# T113-S3 register map
Vendor: Allwinner; Series: T113-S3; File version: 0.1
CPU: other 0, little endian, MPU, no FPU, 0 interrupt priority bits
Registers are 32-bit, read-write, reset 0x0 unless marked. A register's access mark holds for its fields unless they carry their own. Offsets are from the block's base; [hi:lo] are bit positions; {n}, {i} and the like mark numbered series.

## UART0
Base 0x02500000
Same registers: UART1 0x02500400, UART2 0x02500800, UART3 0x02500C00, UART4 0x02501000, UART5 0x02501400
0x00 UART_DLL — UART Divisor Latch Low Register
  [7:0] DLL — Divisor Latch Low Lower 8 bits of 16 bits, read/write, Divisor Latch Register contains the baud rate divisor for the UART. This register may only be accessed when the DLAB bit ( ) is set and the UART is not busy ( is 0). The output baud rate is equal to the serial clock (SCLK) frequency divided by sixteen times the value of the baud rate divisor, as follows: baud rate = (serial clock freq)/(16 * divisor) . Note that when the Divisor Latch Registers ( and ) are set to 0, the baud clock is disabled and no serial communications occur. Also, once the DLL is set, at least 8 clock cycles of the slowest UART clock should be allowed to pass before transmitting or receiving data.
0x00 UART_RBR — UART Receive Buffer Register
  [7:0] RBR ro — Receiver Buffer Register Data byte received on the serial input port (sin) in UART mode, or the serial infrared input (sir_in) in infrared mode. The data in this register is valid only if the Data Ready (DR) bit in is set. If in FIFO mode and FIFOs are enabled (The [0] is set to 1), this register accesses the head of the receive FIFO. If the receive FIFO is full and this register can not read before the next data character arrives, then the data already in the FIFO are preserved, but any incoming data are lost and an overrun error occurs.
0x00 UART_THR — UART Transmit Holding Register
  [7:0] THR wo — Transmit Holding Register Data is transmitted on the serial output port (SOUT) in UART mode or the serial infrared output (sir_out_n) in infrared mode. Data should only be written to the when the THRE bit ( ) is set. If in FIFO mode and FIFOs are enabled ( = 1) and THRE is set, the 16 number of characters data may be written to the before the FIFO is full. When the FIFO is full, any written data results in the written data being lost.
0x04 UART_DLH — UART Divisor Latch High Register
  [7:0] DLH — Divisor Latch High Upper 8 bits of 16 bits, read/write, Divisor Latch Register contains the baud rate divisor for the UART. This register may only be accessed when the DLAB bit ( [7]) is set and the UART is not busy ( [0] is 0). The output baud rate is equal to the serial clock (SCLK) frequency divided by sixteen times the value of the baud rate divisor, as follows: baud rate = (serial clock freq)/(16 * divisor) . Note that when the Divisor Latch Registers ( and ) is set to 0, the baud clock is disabled and no serial communications occur. Also, once the DLH is set, at least 8 clock cycles of the slowest UART clock should be allowed to pass before transmitting or receiving data.
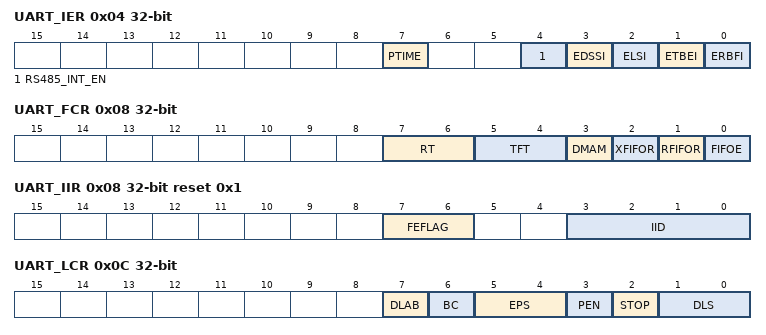
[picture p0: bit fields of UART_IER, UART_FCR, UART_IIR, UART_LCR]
0x04 UART_IER — UART Interrupt Enable Register
  [all] fields
    0=Disable; 1=Enable
  [7] PTIME — Programmable THRE Interrupt Mode Enable This is used to enable/disable the generation of THRE Interrupt. 0: Disable 1: Enable
  [4] RS485_INT_EN — RS485 Interrupt Enable 0: Disable 1: Enable
  [3] EDSSI — Enable Modem Status Interrupt This is used to enable/disable the generation of Modem Status Interrupt. This is the fourth highest priority interrupt. 0: Disable 1: Enable
  [2] ELSI — Enable Receiver Line Status Interrupt This is used to enable/disable the generation of Receiver Line Status Interrupt. This is the highest priority interrupt. 0: Disable 1: Enable
  [1] ETBEI — Enable Transmit Holding Register Empty Interrupt This is used to enable/disable the generation of Transmitter Holding Register Empty Interrupt. This is the third-highest priority interrupt. 0: Disable 1: Enable
  [0] ERBFI — Enable Received Data Available Interrupt This is used to enable/disable the generation of Received Data Available Interrupt and the Character Timeout Interrupt (if in FIFO mode and FIFOs enabled). These are the second-highest priority interrupt. 0: Disable 1: Enable
0x08 UART_FCR — UART FIFO Control Register
  [7:6] RT wo — RCVR Trigger This is used to select the trigger level in the receiver FIFO when the Received Data Available Interrupt is generated. In the autoflow control mode, it is used to determine when the rts_n signal is de-asserted. It also determines when the dma_rx_req_n signal is asserted in certain modes of operation. 00: 1 character in the FIFO 01: FIFO 25% full 10: FIFO 50% full 11: FIFO-2 less than full
    0=1 character in the FIFO; 1=FIFO_25_percent__full (FIFO 25% full); 2=FIFO_50_percent__full (FIFO 50% full); 3=FIFO_minus_2_less (FIFO-2 less than full)
  [5:4] TFT wo — TX Empty Trigger This is used to select the empty threshold level when the THRE Interrupts are generated and the mode is active. It also determines when the dma_tx_req_n signal is asserted in certain modes of operation. 00: FIFO empty 01: 2 characters in the FIFO 10: FIFO 25% full 11: FIFO 50% full
    0=FIFO_empty; 1=2 characters in the FIFO; 2=FIFO_25_percent__full (FIFO 25% full); 3=FIFO_50_percent__full (FIFO 50% full)
  [3] DMAM wo — DMA Mode 0: Mode 0 In this mode, when the PTE in UART_HALT is high and TX FIFO is enabled, the TX DMA request will be set when the TFL in UART_TFL is less than or equal to FIFO Trigger Level (otherwise it will be cleared). When the PTE is high and TX FIFO is disabled, the TX DMA request will be set only if the THR in UART_THR is empty. If the PTE is low, the TX DMA request will be set only if the TX FIFO (TX FIFO enabled) or THR (TX FIFO disabled) is empty. When the DMA_PTE_RX in UART_HALT is high and RX FIFO is enabled, the RX DRQ will be set only if the RFL in UART_RFL is equal to or more than FIFO Trigger Level, otherwise, it will be cleared. 1: Mode 1 In this mode, TX FIFO should be enabled. If the PTE in is high, the TX DMA request will be set when the TFL in is less than or equal to FIFO Trigger Level; If the PTE is low, the TX DMA request will be set when TX FIFO is empty. Once the request is set, it is cleared only when TX FIFO is full. If the RFL in UART_RFL is equal to or more than FIFO Trigger Level or there is a character timeout, the RX DRQ will be set; Once the RX DRQ is set, it is cleared only when RX FIFO (RX FIFO enabled) or RBR (RX FIFO disabled) is empty.
    0=Mode 0 In this mode, when the PTE in UART_HALT is high and TX FIFO is enabled, the TX DMA request will be set when the TFL in UART_TFL is less than or equal to FIFO Trigger Level (otherwise it will be cleared). When the PTE is high and TX FIFO is disabled, the TX DMA request will be set only if the THR in UART_THR is empty. If the PTE is low, the TX DMA request will be set only if the TX FIFO (TX FIFO enabled) or THR (TX FIFO disabled) is empty. When the DMA_PTE_RX in UART_HALT is high and RX FIFO is enabled, the RX DRQ will be set only if the RFL in UART_RFL is equal to or more than FIFO Trigger Level, otherwise, it will be cleared.; 1=Mode 1 In this mode, TX FIFO should be enabled. If the PTE in is high, the TX DMA request will be set when the TFL in is less than or equal to FIFO Trigger Level; If the PTE is low, the TX DMA request will be set when TX FIFO is empty. Once the request is set, it is cleared only when TX FIFO is full. If the RFL in UART_RFL is equal to or more than FIFO Trigger Level or there is a character timeout, the RX DRQ will be set; Once the RX DRQ is set, it is cleared only when RX FIFO (RX FIFO enabled) or RBR (RX FIFO disabled) is empty.
  [2] XFIFOR wo — XMIT FIFO Reset The bit resets the control part of the transfer FIFO and treats the FIFO as empty. This also de-asserts the DMA TX request. It is 'self-cleared'. It is not necessary to clear this bit.
  [1] RFIFOR wo — RCVR FIFO Reset The bit resets the control part of the receive FIFO and treats the FIFO as empty. This also de-asserts the DMA RX request. It is 'self-cleared'. It is not necessary to clear this bit.
  [0] FIFOE wo — Enable FIFOs The bit enables/disables the transmitting (XMIT) and receiving (RCVR) FIFOs. Whenever the value of this bit is changed, both the XMIT and RCVR controller part of FIFOs is reset.
0x08 UART_IIR reset 0x1 — UART Interrupt Identity Register
  [7:6] FEFLAG ro — FIFOs Enable Flag This is used to indicate whether the FIFOs are enabled or disabled. 00: Disable 11: Enable
    0=Disable; 3=Enable
  [3:0] IID ro — Interrupt ID This indicates the highest priority pending interrupt which can be one of the following types. 0000: modem status 0001: no interrupt pending 0010: THR empty 0011: RS485 Interrupt 0100: received data available 0110: receiver line status 0111: busy detect 1100: character timeout The bit 3 indicates an interrupt can only occur when the FIFOs are enabled and used to distinguish a Character Timeout condition interrupt.
    0=modem_status; 1=no interrupt pending; 2=THR_empty; 3=RS485 (RS485 Interrupt); 4=received data available; 6=receiver line status; 7=busy_detect; 12=character timeout The bit 3 indicates an interrupt can only occur when the FIFOs are enabled and used to distinguish a Character Timeout condition interrupt
0x0C UART_LCR — UART Line Control Register
  [7] DLAB — Divisor Latch Access Bit It is writable only when UART is not busy (UART_USR[0] is 0) and always readable. This bit is used to enable the reading and writing of the Divisor Latch register (UART_DLL and UART_DLH) to set the baud rate of the UART. This bit must be cleared after the initial baud rate setup in order to access other registers. 0: Select RX Buffer Register (UART_RBR)/TX Holding Register (UART_THR) and Interrupt Enable Register (UART_IER) 1: Select Divisor Latch LS Register (UART_DLL) and Divisor Latch MS Register (UART_DLM)
    0=Select RX Buffer Register (UART_RBR)/TX Holding Register (UART_THR) and Interrupt Enable Register (UART_IER); 1=Select Divisor Latch LS Register (UART_DLL) and Divisor Latch MS Register (UART_DLM)
  [6] BC — Break Control Bit This is used to cause a break condition to be transmitted to the receiving device. If set to 0, the serial output is forced to the spacing (logic 0) state. When not in Loopback mode, as determined by UART_MCR[4], the SOUT line is forced low until the Break bit is cleared. If SIR_MODE is enabled and active (UART_MCR[6] is set to 1), the sir_out_n line is continuously pulsed. When in Loopback mode, the break condition is internally looped back to the receiver and the sir_out_n line is forced low.
  [5:4] EPS — Even Parity Select It is writable only when UART is not busy (UART_USR[0] is 0). This is used to select the even and odd parity when the PEN is enabled (the UART_LCR[3] is set to 1). Setting the UART_LCR[5] is unset to reverse the LCR[4]. 00: Odd Parity 01: Even Parity 1X: Reverse LCR[4] In RS485 mode, it is the 9th bit--address bit. 11: 9th bit = 0, indicates that this is a data byte. 10: 9th bit = 1, indicates that this is an address byte.
  [3] PEN — Parity Enable It is writable only when UART is not busy (UART_USR[0] is 0) and always readable. This bit is used to enable and disable parity generation and detection in transmitted and received serial characters respectively. 0: Parity disabled 1: Parity enabled
    0=Parity_disabled; 1=Parity_enabled
  [2] STOP — Number of stop bits It is writable only when UART is not busy (UART_USR[0] is 0) and always readable. This is used to select the number of stop bits per character that the peripheral transmits and receives. If set to 0, one stop bit is transmitted in the serial data. If set to 1 and the data bits are set to 5 (UART_LCR[1:0] is 0), one and a half stop bit is transmitted. Otherwise, two stop bits are transmitted. Note that regardless of the number of stop bits selected, the receiver checks only the first stop bit. 0: 1 stop bit 1: 1.5 stop bits when DLS (LCR[1:0]) is zero, else 2 stop bit
    0=1 stop bit; 1=_1_point_5 (1.5 stop bits when DLS (LCR[1:0]) is zero, else 2 stop bit)
  [1:0] DLS — Data Length Select It is writable only when UART is not busy (UART_USR[0] is 0) and always readable. This is used to select the count of bits in a transmitted or received frame. 00: 5 bits 01: 6 bits 10: 7 bits 11: 8 bits
    {v}=_{v+5}_bits (v=0..3)
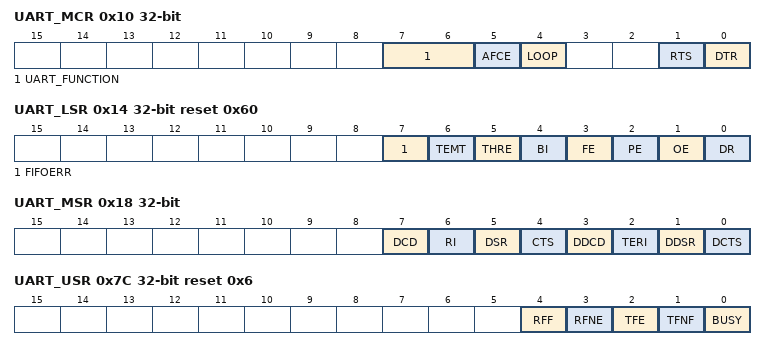
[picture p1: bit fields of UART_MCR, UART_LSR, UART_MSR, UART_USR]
0x10 UART_MCR — UART Modem Control Register
  [7:6] UART_FUNCTION — Select IrDA or RS485 00: UART Mode 01: IrDA SIR Mode 10: RS485 Mode 11: Reserved
    0=UART (UART Mode); 1=IrDA SIR Mode; 2=RS485 (RS485 Mode)
  [5] AFCE — Auto Flow Control Enable When FIFOs are enabled and the AFCE bit is set, the AutoFlow Control is enabled. 0: Auto Flow Control mode disabled 1: Auto Flow Control mode enabled
    0=disabled (Auto Flow Control mode disabled); 1=enabled (Auto Flow Control mode enabled)
  [4] LOOP — Loop Back Mode 0: Normal Mode 1: Loop Back Mode This is used to put the UART into a diagnostic mode for test purposes. If operating in UART mode (SIR_MODE != Enabled or not active, UART_MCR[6] is set to 0), the data on the SOUT line is held high, while serial data output is looped back to the sin line, internally. In this mode, all the interrupts are fully functional. Also, in loopback mode, the modem control inputs (dsr_n, cts_n, ri_n, dcd_n) are disconnected and the modem control outputs (dtr_n, rts_n, out1_n, out2_n) are looped back to the inputs, internally. If operating in infrared mode (SIR_MODE == Enabled AND active, UART_MCR[6] is set to 1), the data on the sir_out_n line is held low, while serial data output is inverted and looped back to the sir_in line.
    0=Normal Mode; 1=Loop Back Mode This is used to put the UART into a diagnostic mode for test purposes. If operating in UART mode (SIR_MODE != Enabled or not active, UART_MCR[6] is set to 0), the data on the SOUT line is held high, while serial data output is looped back to the sin line, internally. In this mode, all the interrupts are fully functional. Also, in loopback mode, the modem control inputs (dsr_n, cts_n, ri_n, dcd_n) are disconnected and the modem control outputs (dtr_n, rts_n, out1_n, out2_n) are looped back to the inputs, internally. If operating in infrared mode (SIR_MODE == Enabled AND active, UART_MCR[6] is set to 1), the data on the sir_out_n line is held low, while serial data output is inverted and looped back to the sir_in line.
  [1] RTS — Request to Send This is used to directly control the Request to Send (rts_n) output. The RTS (rts_n) output is used to inform the modem or data set that the UART is ready to exchange data. When Auto RTS Flow Control is not enabled ( is set to 0), the rts_n signal is set low by programming UART_MCR[1] (RTS) to a high. In Auto Flow Control, AFCE_MODE == Enabled and active ( is set to 1) and FIFOs enable (UART_FCR[0] is set to 1), the rts_n output is controlled in the same way, but is also gated with the receiver FIFO threshold trigger (rts_n is inactive high when above the threshold). The rts_n signal is de-asserted when UART_MCR[1] is set low. 0: rts_n de-asserted (logic 1) 1: rts_n asserted (logic 0) Note that in Loopback mode (UART_MCR[4] is set to 1), the rts_n output is held inactive high while the value of this location is internally looped back to an input.
    0=n_deasserted (rts_n de-asserted (logic 1)); 1=n_asserted (rts_n asserted (logic 0) Note that in Loopback mode (UART_MCR[4] is set to 1), the rts_n output is held inactive high while the value of this location is internally looped back to an input.)
  [0] DTR — Data Terminal Ready This is used to directly control the Data Terminal Ready (dtr_n) output. The value written to this location is inverted and driven out on dtr_n. 0: dtr_n de-asserted (logic 1) 1: dtr_n asserted (logic 0) The DTR output is used to inform the modem or data set that the UART is ready to establish communications. Note that in Loopback mode (UART_MCR[4] is set to 1), the dtr_n output is held inactive high while the value of this location is internally looped back to an input.
    0=n_deasserted (dtr_n de-asserted (logic 1)); 1=n_asserted (dtr_n asserted (logic 0) The DTR output is used to inform the modem or data set that the UART is ready to establish communications. Note that in Loopback mode (UART_MCR[4] is set to 1), the dtr_n output is held inactive high while the value of this location is internally looped back to an input.)
0x14 UART_LSR reset 0x60 — UART Line Status Register
  [7] FIFOERR ro — RX Data Error in FIFO When FIFOs are disabled, this bit is always 0. When FIFOs are enabled, this bit is set to `1` when there is at least one PE, FE, or BI in the RX FIFO. It is cleared by reading from the UART_LSR register, there are no subsequent errors in the FIFO.
  [6] TEMT ro — Transmitter Empty If the FIFOs are disabled, this bit is set to "1" whenever the TX Holding Register (UART_THR) and the TX Shift Register are empty. If the FIFOs are enabled, this bit is set whenever the TX FIFO and the TX Shift Register are empty. In both cases, this bit is cleared when a byte is written to the TX data channel.
  [5] THRE ro — TX Holding Register Empty If the FIFOs are disabled, this bit is set to "1" when the TX Holding Register (UART_THR) is empty and ready to accept new data and it is cleared when the CPU writes to the TX Holding Register. If the FIFOs are enabled, this bit is set to "1" whenever the TX FIFO is empty and it is cleared when at least one byte is written to the TX FIFO.
  [4] BI ro — Break Interrupt This is used to indicate the detection of a break sequence on the serial input data. If in UART mode (SIR_MODE == Disabled), it is set when the serial input, sir_in, is held in a logic '0' state for longer than the sum of + + + . If in infrared mode (SIR_MODE == Enabled), it is set when the serial input, sir_in, is continuously pulsed to logic '0' for longer than the sum of + + + . A break condition on serial input causes one and only one character, consisting of all zeros, to be received by the UART. In the FIFO mode, the character associated with the break condition is carried through the FIFO and is revealed when the character is at the top of the FIFO. Reading the UART_LSR clears the BI bit. In the non-FIFO mode, the BI indication occurs immediately and persists until the UART_LSR is read.
  [3] FE ro read-clears — Framing Error This is used to indicate the occurrence of a framing error in the receiver. A framing error occurs when the receiver does not detect a valid STOP bit in the received data. In the FIFO mode, since the framing error is associated with a character received, it is revealed when the character with the framing error is at the top of the FIFO. When a framing error occurs, the UART tries to resynchronize. It does this by assuming that the error was due to the start bit of the next character and then continues receiving the other bit i.e. data, and/or parity and stop. It should be noted that the Framing Error (FE) bit (UART_LSR[3]) is set if a break interrupt has occurred, as indicated by Break Interrupt (BI) bit (UART_LSR[4]). 0: no framing error 1: framing error Reading the UART_LSR clears the FE bit.
    0=no framing error; 1=framing error Reading the UART_LSR clears the FE bit
  [2] PE ro read-clears — Parity Error This is used to indicate the occurrence of a parity error in the receiver if the Parity Enable (PEN) bit (UART_LCR[3]) is set. In the FIFO mode, since the parity error is associated with a character received, it is revealed when the character with the parity error arrives at the top of the FIFO. It should be noted that the Parity Error (PE) bit (UART_LSR[2]) is set if a break interrupt has occurred, as indicated by Break Interrupt (BI) bit (UART_LSR[4]). 0: no parity error 1: parity error Reading the UART_LSR clears the PE bit.
    0=no parity error; 1=parity error Reading the UART_LSR clears the PE bit
  [1] OE ro read-clears — Overrun Error This occurs if a new data character was received before the previous data was read. In the non-FIFO mode, the OE bit is set when a new character arrives in the receiver before the previous character was read from the UART_RBR. When this happens, the data in the UART_RBR is overwritten. In the FIFO mode, an overrun error occurs when the FIFO is full and a new character arrives at the receiver. The data in the FIFO is retained and the data in the receive shift register is lost. 0: no overrun error 1: overrun error Reading the UART_LSR clears the OE bit.
    0=no overrun error; 1=overrun error Reading the UART_LSR clears the OE bit
  [0] DR ro — Data Ready This is used to indicate that the receiver contains at least one character in the UART_RBR or the receiver FIFO. 0: no data ready 1: data ready This bit is cleared when the UART_RBR is read in non-FIFO mode, or when the receiver FIFO is empty, in FIFO mode.
    0=no data ready; 1=data ready This bit is cleared when the UART_RBR is read in non-FIFO mode, or when the receiver FIFO is empty, in FIFO mode
0x18 UART_MSR — UART Modem Status Register
  [7] DCD ro — Line State of Data Carrier Detect This is used to indicate the current state of the modem control line dcd_n. This bit is the complement of dcd_n. When the Data Carrier Detect input (dcd_n) is asserted it is an indication that the carrier has been detected by the modem or data set. 0: dcd_n input is de-asserted (logic 1) 1: dcd_n input is asserted (logic 0)
    0=deasserted (dcd_n input is de-asserted (logic 1)); 1=asserted (dcd_n input is asserted (logic 0))
  [6] RI ro — Line State of Ring Indicator This is used to indicate the current state of the modem control line ri_n. This bit is the complement of ri_n. When the Ring Indicator input (ri_n) is asserted it is an indication that a telephone ringing signal has been received by setting the modem or data. 0: ri_n input is de-asserted (logic 1) 1: ri_n input is asserted (logic 0)
    0=deasserted (ri_n input is de-asserted (logic 1)); 1=asserted (ri_n input is asserted (logic 0))
  [5] DSR ro — Line State of Data Set Ready This is used to indicate the current state of the modem control line dsr_n. This bit is the complement of the dsr_n. When the Data Set Ready input (dsr_n) is asserted, it is an indication that the modem or data set is ready to establish communication with UART. 0: dsr_n input is de-asserted (logic 1) 1: dsr_n input is asserted (logic 0) In Loopback Mode (UART_MCR[4] is set to 1), the DSR is the same as the DTR (UART_MCR[0]).
    0=deasserted (dsr_n input is de-asserted (logic 1)); 1=asserted (dsr_n input is asserted (logic 0) In Loopback Mode (UART_MCR[4] is set to 1), the DSR is the same as the DTR (UART_MCR[0]).)
  [4] CTS ro — Line State of Clear To Send This is used to indicate the current state of the modem control line cts_n. This bit is the complement of cts_n. When the Clear to Send input (cts_n) is asserted, it is an indication that the modem or data set is ready to exchange data with UART. 0: cts_n input is de-asserted (logic 1) 1: cts_n input is asserted (logic 0) In Loopback Mode (UART_MCR[4] = 1), the CTS is the same as the RTS (UART_MCR[1]).
    0=deasserted (cts_n input is de-asserted (logic 1)); 1=asserted (cts_n input is asserted (logic 0) In Loopback Mode (UART_MCR[4] = 1), the CTS is the same as the RTS (UART_MCR[1]).)
  [3] DDCD ro read-clears — Delta Data Carrier Detect This is used to indicate that the modem control line dcd_n has changed since the last time the UART_MSR was read. 0: no change on dcd_n since the last read of UART_MSR 1: change on dcd_n since the last read of UART_MSR Reading the UART_MSR clears the DDCD bit.
    0=no change on dcd_n since the last read of UART_MSR; 1=change on dcd_n since the last read of UART_MSR Reading the UART_MSR clears the DDCD bit
  [2] TERI ro read-clears — Trailing Edge Ring Indicator This is used to indicate that a change in the input ri_n (from an active-low to an inactive-high state) has occurred since the last time the UART_MSR was read. 0: no change on ri_n since the last read of UART_MSR 1: change on ri_n since the last read of UART_MSR Reading the UART_MSR clears the TERI bit.
    0=no change on ri_n since the last read of UART_MSR; 1=change on ri_n since the last read of UART_MSR Reading the UART_MSR clears the TERI bit
  [1] DDSR ro read-clears — Delta Data Set Ready This is used to indicate that the modem control line dsr_n has changed since the last time the UART_MSR was read. 0: no change on dsr_n since the last read of UART_MSR 1: change on dsr_n since the last read of UART_MSR Reading the UART_MSR clears the DDSR bit. In Loopback Mode (UART_MCR[4] = 1), the DDSR reflects changes on the DTR (UART_MCR[0] .
    0=no change on dsr_n since the last read of UART_MSR; 1=change on dsr_n since the last read of UART_MSR Reading the UART_MSR clears the DDSR bit. In Loopback Mode (UART_MCR[4] = 1), the DDSR reflects changes on the DTR (UART_MCR[0] .
  [0] DCTS ro read-clears — Delta Clear to Send This is used to indicate that the modem control line cts_n has changed since the last time the UART_MSR was read. 0: no change on ctsdsr_n since the last read of UART_MSR 1: change on ctsdsr_n since the last read of UART_MSR Reading the UART_MSR clears the DCTS bit. In Loopback Mode (UART_MCR[4] = 1), the DCTS reflects changes on the RTS (UART_MCR[1]).
    0=no change on ctsdsr_n since the last read of UART_MSR; 1=change on ctsdsr_n since the last read of UART_MSR Reading the UART_MSR clears the DCTS bit. In Loopback Mode (UART_MCR[4] = 1), the DCTS reflects changes on the RTS (UART_MCR[1]).
0x1C UART_SCH — UART Scratch Register
  [7:0] SCRATCH_REG — Scratch Register This register is for programmers to use as a temporary storage space. It has no defined purpose in the UART.
0x7C UART_USR reset 0x6 — UART Status Register
  [4] RFF ro — RX FIFO Full This is used to indicate that the RX FIFO is completely full. 0: RX FIFO not full 1: RX FIFO Full This bit is cleared when the RX FIFO is no longer full.
    0=RX_FIFO_not_full; 1=RX FIFO Full This bit is cleared when the RX FIFO is no longer full
  [3] RFNE ro — RX FIFO Not Empty This is used to indicate that the RX FIFO contains one or more entries. 0: RX FIFO is empty 1: RX FIFO is not empty This bit is cleared when the RX FIFO is empty.
    0=empty (RX FIFO is empty); 1=not_empty (RX FIFO is not empty This bit is cleared when the RX FIFO is empty.)
  [2] TFE ro — TX FIFO Empty This is used to indicate that the TX FIFO is completely empty. 0: TX FIFO is not empty 1: TX FIFO is empty This bit is cleared when the TX FIFO is no longer empty.
    0=not_empty (TX FIFO is not empty); 1=empty (TX FIFO is empty This bit is cleared when the TX FIFO is no longer empty.)
  [1] TFNF ro — TX FIFO Not Full This is used to indicate that the TX FIFO is not full. 0: TX FIFO is full 1: TX FIFO is not full This bit is cleared when the TX FIFO is full.
    0=full (TX FIFO is full); 1=not_full (TX FIFO is not full This bit is cleared when the TX FIFO is full.)
  [0] BUSY ro — UART Busy Bit 0: Idle or inactive 1: Busy
    0=Idle or inactive; 1=Busy
0x80 UART_TFL — UART Transmit FIFO Level Register
  [8:0] TFL ro — TX FIFO Level The bit indicates the number of data entries in the TX FIFO.
0x84 UART_RFL — UART Receive FIFO Level Register
  [8:0] RFL ro — RX FIFO Level The bit indicates the number of data entries in the RX FIFO. UART_RXDMA_CTRL [0] is set to 1).
0x88 UART_HSK reset 0xA5 — UART DMA Handshake Configuration Register
  [7:0] HANDSHAKE — Handshake configuration 0xA5: DMA wait cycle mode 0xE5: DMA handshake mode
    165=DMA wait cycle mode; 229=DMA_handshake_mode
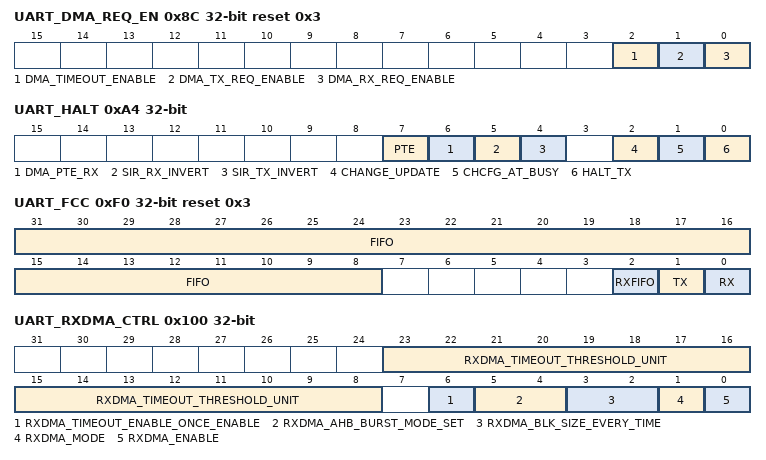
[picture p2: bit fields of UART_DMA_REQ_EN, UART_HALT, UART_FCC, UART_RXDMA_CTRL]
0x8C UART_DMA_REQ_EN reset 0x3 — UART DMA Request Enable Register
  [all] fields
    0=Disable; 1=Enable
  [2] DMA_TIMEOUT_ENABLE — DMA Timeout Enable 0: Disable 1: Enable
  [1] DMA_TX_REQ_ENABLE — DMA TX REQ Enable 0: Disable 1: Enable
  [0] DMA_RX_REQ_ENABLE — DMA RX REQ Enable 0: Disable 1: Enable
0xA4 UART_HALT — UART Halt TX Register
  [7] PTE — The sending of TX_REQ In DMA1 mode (FIFO on), if the PTE is set to 1 when the TFL in UART_TFL is less than or equal to the trigger value, the controller sends the DMA request. If the PTE is set to 0, when FIFO is empty, the controller sends the DMA request. The DMA request will stop when FIFO is full. In DMA0 mode, if the PTE is set to 1 and FIFO is on, when the TFL in UART_TFL is less than or equal to the trigger value, the controller sends DMA request. If the PTE is set to 1 and FIFO off, when the THR in UART_THR is empty, the controller sends DMA request. If the PTE is set to 0, when FIFO(FIFO Enable) or THR(FIFO Enable) is empty, the controller sends DMA request. Otherwise, the DMA request is cleared.
  [6] DMA_PTE_RX — The Transmission of RX_DRQ In DMA1 mode, when RFL is more than or equal to the trigger value, or a receive timeout has occurred, the controller sends DRQ. In DMA0 mode, when DMA_PTE_RX = 1 and FIFO is on, if RFL is more than or equal to trig, the controller sends DRQ, else DRQ is cleared. In other cases, once the received data is valid, the controller sends DRQ.
  [5] SIR_RX_INVERT — SIR RX Pulse Polarity Invert 0: Not invert receiver signal 1: Invert receiver signal
    0=Not invert receiver signal; 1=Invert receiver signal
  [4] SIR_TX_INVERT — SIR TX Pulse Polarity Invert 0: Not invert transmit pulse 1: Invert transmit pulse
    0=Not invert transmit pulse; 1=Invert transmit pulse
  [2] CHANGE_UPDATE — After the user uses UART_HALT[1] to change the baud rate or LCR configuration, write 1 to update the configuration and wait this bit to self-clear to 0 to finish update process. Writing 0 to this bit has no effect. 1: Update trigger, self-clear to 0 when finish update.
    1=Update trigger, self-clear to 0 when finish update
  [1] CHCFG_AT_BUSY — This is an enable bit for the user to change LCR register configuration and baud rate register (UART_DLH and UART_DLL) when the UART is busy. 1: Enable change when busy
    1=Enable change when busy
  [0] HALT_TX — Halt TX This register is used to halt transmissions for testing, so that the transmit FIFO can be filled by the master when FIFOs are implemented and enabled. 0 : Halt TX disabled 1 : Halt TX enabled
0xB0 UART_DBG_DLL — UART Debug DLL Register
  [7:0] DEBUG ro — DLL
0xB4 UART_DBG_DLH — UART Debug DLH Register
  [7:0] DEBUG ro — DLH
0xF0 UART_FCC reset 0x3
  [31:8] FIFO ro — Depth Indicates the depth of TX/RX FIFO
  [2] RXFIFO — Clock Mode 0: Sync mode, writing/reading clocks use apb clock 1: Sync mode, writing clock uses apb clock, reading clock uses ahb clock
    0=comma__writing_slash_reading (Sync mode, writing/reading clocks use apb clock); 1=comma__writing (Sync mode, writing clock uses apb clock, reading clock uses ahb clock)
  [1] TX — FIFO Clock Enable 0: Clock disable 1: Clock enable
    0=Clock_disable; 1=Clock_enable
  [0] RX — FIFO Clock Enable 0: Clock disable 1: Clock enable
    0=Clock_disable; 1=Clock_enable
0x100 UART_RXDMA_CTRL
  [23:8] RXDMA_TIMEOUT_THRESHOLD_UNIT — RXDMA Timeout Threshold Unit is 1 UART bit time Note that this field is only configurable when RXDMA Busy is 0.
  [6] RXDMA_TIMEOUT_ENABLE_ONCE_ENABLE — RXDMA Timeout Enable Once enable, the DMA starts a transfer even the data entries in RX FIFO do not reach BLK_SIZE. Note that this field is only configurable when RXDMA Busy is 0.
  [5:4] RXDMA_AHB_BURST_MODE_SET — RXDMA AHB Burst Mode Set for AHB port burst supported INCR8 is recommended, while INCR16 may be unsupported due to the system bus. 00: SIGNLE 01: INCR4 10: INCR8 11: INCR16 Note that this field is only configurable while RXDMA Busy is 0.
    0=SIGNLE; 1=INCR4; 2=INCR8; 3=INCR16 (INCR16 Note that this field is only configurable while RXDMA Busy is 0.)
  [3:2] RXDMA_BLK_SIZE_EVERY_TIME — RXDMA BLK SIZE Every time when data entries in RX FIFO reach BLK_SIZE, start a DMA block transfer. It is recommended that the block size no more than RX FIFO Depth. 00: 8 bytes 01: 16 bytes 10: 32 bytes 11: 64 bytes Note that this field is only configurable while RXDMA Busy is 0.
    0=8 bytes; 1=16 bytes; 2=32 bytes; 3=64 bytes Note that this field is only configurable while RXDMA Busy is 0
  [1] RXDMA_MODE — RXDMA Mode 0: Continous 1: Limited When data transferred reaches the limited count set in RXDMA LIMIT, the DMA stops and the RXDMA Start bit is cleared automatically. Note that this field is only configurable while RXDMA Busy is 0.
    0=Continous; 1=Limited When data transferred reaches the limited count set in RXDMA LIMIT, the DMA stops and the RXDMA Start bit is cleared automatically. Note that this field is only configurable while RXDMA Busy is 0.
  [0] RXDMA_ENABLE — RXDMA Enable 0: RXDMA Disable 1: RXDMA Enable Note that if the software turns off this bit, the RXDMA will stop after the current block transfer completes, then the software should do a reset to the RX FIFO before re-enable.
    0=RXDMA_Disable; 1=RXDMA Enable Note that if the software turns off this bit, the RXDMA will stop after the current block transfer completes, then the software should do a reset to the RX FIFO before re-enable
0x104 UART_RXDMA_STR
  [0] RXDMA — Start Only valid when RXDMA mode is set to 1, it is auto cleared when data transferred reaches the RXDMA Limit Size.
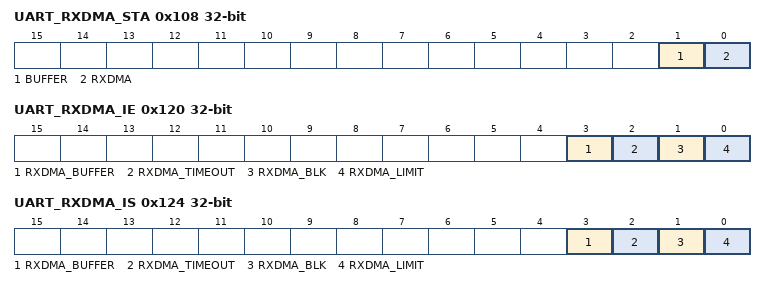
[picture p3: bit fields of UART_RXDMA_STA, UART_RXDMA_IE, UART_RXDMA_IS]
0x108 UART_RXDMA_STA
  [1] BUFFER ro — Buffer Read Address Updating 0: Buffer Read Address Register is ready for updating 1: Buffer Read Address Register is busy for updating The software should not update Buffer Read Address Register until this bit is 0.
    0=ready (Buffer Read Address Register is ready for updating); 1=busy (Buffer Read Address Register is busy for updating The software should not update Buffer Read Address Register until this bit is 0.)
  [0] RXDMA ro — BUSY 0: RXDMA is idle 1: RXDMA is busy
    0=is_idle (RXDMA is idle); 1=is_busy (RXDMA is busy)
0x10C UART_RXDMA_LMT
  [15:0] RXDMA — Limit Size Only valid when RXDMA Mode is set to 1, and the unit is byte. Note that this field is only configurable while RXDMA Busy is 0.
0x110 UART_RXDMA_SADDRL
  [31:0] RXDMA — Buffer Start Address [31:0] Byte address Note that this field is only configurable while RXDMA Busy is 0.
0x114 UART_RXDMA_SADDRH
  [1:0] RXDMA — Buffer Start Address [33:32] Byte address Note that this field is only configurable while RXDMA Busy is 0.
0x118 UART_RXDMA_BL
  [15:0] RXDMA — Buffer Length Unit is byte Note that this field is only configurable while RXDMA Busy is 0.
0x120 UART_RXDMA_IE
  [3] RXDMA_BUFFER — RXDMA Buffer Overrun RXDMA Buffer Overrun Interrupt Enable
  [2] RXDMA_TIMEOUT — RXDMA Timeout Done RXDMA Timeout Done Interrupt Enable
  [1] RXDMA_BLK — RXDMA BLK Done RXDMA BLK Done Interrupt Enable
  [0] RXDMA_LIMIT — RXDMA Limit Done RXDMA Limit Done Interrupt Enable
0x124 UART_RXDMA_IS
  [3] RXDMA_BUFFER write-1-clears — RXDMA Buffer Overrun Asserted when the RXDMA buffer is overflow.
  [2] RXDMA_TIMEOUT write-1-clears — RXDMA Timeout Done Asserted when a DMA transfer caused by timeout is done.
  [1] RXDMA_BLK write-1-clears — RXDMA BLK Done Asserted when a DMA block transfer is done.
  [0] RXDMA_LIMIT write-1-clears — RXDMA Limit Done Asserted when data transferred reaches limit size in RXDMA Limit Mode.
0x128 UART_RXDMA_WADDRL
  [31:0] RXDMA ro — Current Write Address[31:0] Updated when every DMA transfer is done It is byte address.
0x12C UART_RXDMA_WADDRH
  [1:0] RXDMA ro — Current Write Address[33:32] Updated when every DMA transfer is done It is byte address.
0x130 UART_RXDMA_RADDRL
  [31:0] RXDMA — Current Read Address[31:0] Software should update this register after reading data in RXDMA Buffer in time It is byte address. The software should not update Buffer Read Address Register until UART_RXDMA_STA[1] is 0. The software should update Read Address High Register first, and then Read Address Low Register, even there is no change on Read Address High Register.
0x134 UART_RXDMA_RADDRH
  [1:0] RXDMA — Current Read Address[33:32] Software should update this register after reading data in RXDMA Buffer in time. It is byte address. The software should not update Buffer Read Address Register until until UART_RXDMA_STA[1] is 0. The software should update Read Address High Register first and then Read Address Low Register , even there is no change on Read Address High Register.
0x138 UART_RXDMA_DCNT
  [15:0] RXDMA ro — Data Count Only valid while RXDMA Mode is set to 1, it is used for counting the data transferred by RXDMA, and is cleared when reaches RXDMA Limit Size. Its unit is byte.
